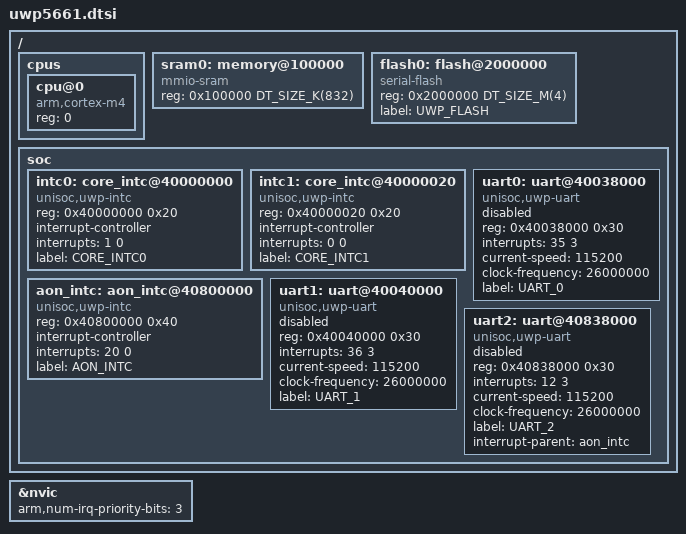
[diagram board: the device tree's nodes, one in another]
/*
 * Copyright (c) 2018, UNISOC Incorporated
 * Copyright (c) 2019, Manivannan Sadhasivam
 *
 * SPDX-License-Identifier: Apache-2.0
 */

#include <arm/armv7-m.dtsi>
#include <mem.h>


/ {
	cpus {
		#address-cells = <1>;
		#size-cells = <0>;

		cpu@0 {
			device_type = "cpu";
			compatible = "arm,cortex-m4";
			reg = <0>;
		};
	};

	sram0: memory@100000 {
		device_type = "memory";
		compatible = "mmio-sram";
		reg = <0x100000 DT_SIZE_K(832)>;
	};

	flash0: flash@2000000 {
		compatible = "serial-flash";
		reg = <0x2000000 DT_SIZE_M(4)>;
		label = "UWP_FLASH";
	};

	soc {
		intc0: core_intc@40000000 {
			compatible = "unisoc,uwp-intc";
			reg = <0x40000000 0x20>;
			interrupt-controller;
			#interrupt-cells = <2>;
			interrupts = <1 0>;
			label = "CORE_INTC0";
		};

		intc1: core_intc@40000020 {
			compatible = "unisoc,uwp-intc";
			reg = <0x40000020 0x20>;
			interrupt-controller;
			#interrupt-cells = <2>;
			interrupts = <0 0>;
			label = "CORE_INTC1";
		};

		aon_intc: aon_intc@40800000 {
			compatible = "unisoc,uwp-intc";
			reg = <0x40800000 0x40>;
			interrupt-controller;
			#interrupt-cells = <2>;
			interrupts = <20 0>;
			label = "AON_INTC";
		};

		uart0: uart@40038000 {
			compatible = "unisoc,uwp-uart";
			reg = <0x40038000 0x30>;
			interrupts = <35 3>;
			current-speed = <115200>;
			clock-frequency = <26000000>;
			label = "UART_0";
			status = "disabled";
		};

		uart1: uart@40040000 {
			compatible = "unisoc,uwp-uart";
			reg = <0x40040000 0x30>;
			interrupts = <36 3>;
			current-speed = <115200>;
			clock-frequency = <26000000>;
			label = "UART_1";
			status = "disabled";
		};

		uart2: uart@40838000 {
			compatible = "unisoc,uwp-uart";
			reg = <0x40838000 0x30>;
			interrupts = <12 3>;
			current-speed = <115200>;
			clock-frequency = <26000000>;
			label = "UART_2";
			interrupt-parent = <&aon_intc>;
			status = "disabled";
		};
	};
};

&nvic {
	arm,num-irq-priority-bits = <3>;
};
